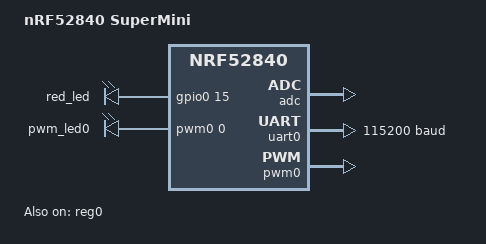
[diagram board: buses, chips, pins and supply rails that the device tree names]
/*
 * Copyright (c) 2025 maminjie <canpool@163.com>
 *
 * SPDX-License-Identifier: Apache-2.0
 */

/dts-v1/;
#include <nordic/nrf52840_qiaa.dtsi>
#include <nordic/nrf52840_partition.dtsi>
#include "nrf52840_supermini-pinctrl.dtsi"
#include <zephyr/dt-bindings/input/input-event-codes.h>

/ {
	model = "nRF52840 SuperMini";
	compatible = "nordic,nrf52840-dk-nrf52840";

	chosen {
		zephyr,console = &uart0;
		zephyr,shell-uart = &uart0;
	};

	leds {
		compatible = "gpio-leds";
		red_led: led_0 {
			gpios = <&gpio0 15 GPIO_ACTIVE_HIGH>;
		};
	};

	pwmleds {
		compatible = "pwm-leds";
		pwm_led0: pwm_led_0 {
			pwms = <&pwm0 0 PWM_MSEC(20) PWM_POLARITY_INVERTED>;
		};
	};

	/* These aliases are provided for compatibility with samples */
	aliases {
		led0 = &red_led;
		pwm-led0 = &pwm_led0;
	};
};

&reg0 {
	status = "okay";
};

&reg1 {
	regulator-initial-mode = <NRF5X_REG_MODE_DCDC>;
};

&adc {
	status = "okay";
};

&uicr {
	gpio-as-nreset;
};

&gpiote {
	status = "okay";
};

&gpio0 {
	status = "okay";
};

&gpio1 {
	status = "okay";
};

&uart0 {
	compatible = "nordic,nrf-uarte";
	status = "okay";
	current-speed = <115200>;
	pinctrl-0 = <&uart0_default>;
	pinctrl-1 = <&uart0_sleep>;
	pinctrl-names = "default", "sleep";
};

&pwm0 {
	status = "okay";
	pinctrl-0 = <&pwm0_default>;
	pinctrl-1 = <&pwm0_sleep>;
	pinctrl-names = "default", "sleep";
};
